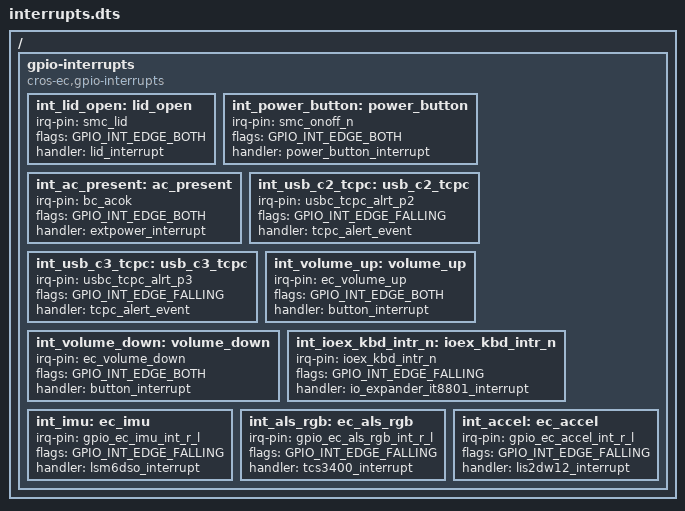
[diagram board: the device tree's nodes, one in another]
/* Copyright 2022 The ChromiumOS Authors
 * Use of this source code is governed by a BSD-style license that can be
 * found in the LICENSE file.
 */
/ {
	gpio-interrupts {
		compatible = "cros-ec,gpio-interrupts";

		int_lid_open: lid_open {
			irq-pin = <&smc_lid>;
			flags = <GPIO_INT_EDGE_BOTH>;
			handler = "lid_interrupt";
		};
		int_power_button: power_button {
			irq-pin = <&smc_onoff_n>;
			flags = <GPIO_INT_EDGE_BOTH>;
			handler = "power_button_interrupt";
		};
		int_ac_present: ac_present {
			irq-pin = <&bc_acok>;
			flags = <GPIO_INT_EDGE_BOTH>;
			handler = "extpower_interrupt";
		};
		int_usb_c2_tcpc: usb_c2_tcpc {
			irq-pin = <&usbc_tcpc_alrt_p2>;
			flags = <GPIO_INT_EDGE_FALLING>;
			handler = "tcpc_alert_event";
		};
		int_usb_c3_tcpc: usb_c3_tcpc {
			irq-pin = <&usbc_tcpc_alrt_p3>;
			flags = <GPIO_INT_EDGE_FALLING>;
			handler = "tcpc_alert_event";
		};
		int_volume_up: volume_up {
			irq-pin = <&ec_volume_up>;
			flags = <GPIO_INT_EDGE_BOTH>;
			handler = "button_interrupt";
		};
		int_volume_down: volume_down {
			irq-pin = <&ec_volume_down>;
			flags = <GPIO_INT_EDGE_BOTH>;
			handler = "button_interrupt";
		};
		int_ioex_kbd_intr_n: ioex_kbd_intr_n {
			irq-pin = <&ioex_kbd_intr_n>;
			flags = <GPIO_INT_EDGE_FALLING>;
			handler = "io_expander_it8801_interrupt";
		};
		int_imu: ec_imu {
			irq-pin = <&gpio_ec_imu_int_r_l>;
			flags = <GPIO_INT_EDGE_FALLING>;
			handler = "lsm6dso_interrupt";
		};
		int_als_rgb: ec_als_rgb {
			irq-pin = <&gpio_ec_als_rgb_int_r_l>;
			flags = <GPIO_INT_EDGE_FALLING>;
			handler = "tcs3400_interrupt";
		};
		int_accel: ec_accel {
			irq-pin = <&gpio_ec_accel_int_r_l>;
			flags = <GPIO_INT_EDGE_FALLING>;
			handler = "lis2dw12_interrupt";
		};
	};
};
